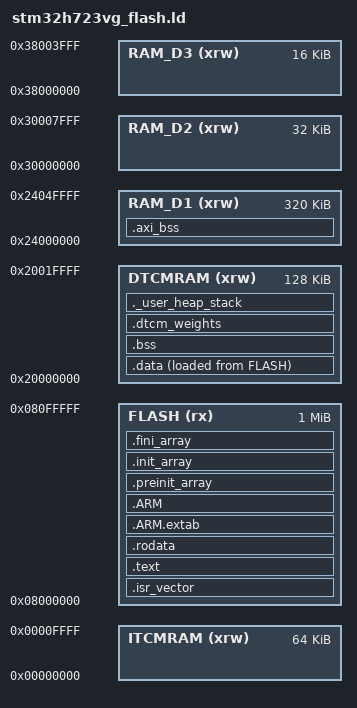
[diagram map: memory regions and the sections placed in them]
/* STM32H723VGT6: 1 MB flash, 128 KB DTCM, 320 KB AXI SRAM.
 * .data/.bss and the stack live in DTCM, which is zero-wait-state and not
 * behind the caches, so benchmark timing does not depend on cache state.
 * .dtcm_weights is a copy target for moving model weights off flash. */
ENTRY(Reset_Handler)

_estack        = ORIGIN(DTCMRAM) + LENGTH(DTCMRAM);
_Min_Heap_Size = 0x200;
_Min_Stack_Size = 0x2000;

MEMORY
{
  ITCMRAM (xrw) : ORIGIN = 0x00000000, LENGTH = 64K
  DTCMRAM (xrw) : ORIGIN = 0x20000000, LENGTH = 128K
  RAM_D1  (xrw) : ORIGIN = 0x24000000, LENGTH = 320K
  RAM_D2  (xrw) : ORIGIN = 0x30000000, LENGTH = 32K
  RAM_D3  (xrw) : ORIGIN = 0x38000000, LENGTH = 16K
  FLASH   (rx)  : ORIGIN = 0x08000000, LENGTH = 1024K
}

SECTIONS
{
  .isr_vector : { . = ALIGN(4); KEEP(*(.isr_vector)) . = ALIGN(4); } >FLASH
  .text : {
    . = ALIGN(4);
    *(.text) *(.text*) *(.glue_7) *(.glue_7t) *(.eh_frame)
    KEEP (*(.init)) KEEP (*(.fini))
    . = ALIGN(4);
    _etext = .;
  } >FLASH
  .rodata : { . = ALIGN(4); *(.rodata) *(.rodata*) . = ALIGN(4); } >FLASH
  .ARM.extab : { *(.ARM.extab* .gnu.linkonce.armextab.*) } >FLASH
  .ARM : { __exidx_start = .; *(.ARM.exidx*) __exidx_end = .; } >FLASH
  .preinit_array : { PROVIDE_HIDDEN(__preinit_array_start = .); KEEP(*(.preinit_array*)) PROVIDE_HIDDEN(__preinit_array_end = .); } >FLASH
  .init_array : { PROVIDE_HIDDEN(__init_array_start = .); KEEP(*(SORT(.init_array.*))) KEEP(*(.init_array*)) PROVIDE_HIDDEN(__init_array_end = .); } >FLASH
  .fini_array : { PROVIDE_HIDDEN(__fini_array_start = .); KEEP(*(SORT(.fini_array.*))) KEEP(*(.fini_array*)) PROVIDE_HIDDEN(__fini_array_end = .); } >FLASH

  _sidata = LOADADDR(.data);
  .data : { . = ALIGN(4); _sdata = .; *(.data) *(.data*) . = ALIGN(4); _edata = .; } >DTCMRAM AT> FLASH

  . = ALIGN(4);
  .bss : { _sbss = .; __bss_start__ = _sbss; *(.bss) *(.bss*) *(COMMON) . = ALIGN(4); _ebss = .; __bss_end__ = _ebss; } >DTCMRAM

  /* Uninitialised scratch for weights relocated out of flash. */
  .dtcm_weights (NOLOAD) : { . = ALIGN(32); *(.dtcm_weights) *(.dtcm_weights*) . = ALIGN(32); } >DTCMRAM
  .axi_bss (NOLOAD) : { . = ALIGN(32); *(.axi_bss) *(.axi_bss*) . = ALIGN(32); } >RAM_D1

  ._user_heap_stack : {
    . = ALIGN(8); PROVIDE(end = .); PROVIDE(_end = .);
    . = . + _Min_Heap_Size; . = . + _Min_Stack_Size; . = ALIGN(8);
  } >DTCMRAM

  .ARM.attributes 0 : { *(.ARM.attributes) }
}
